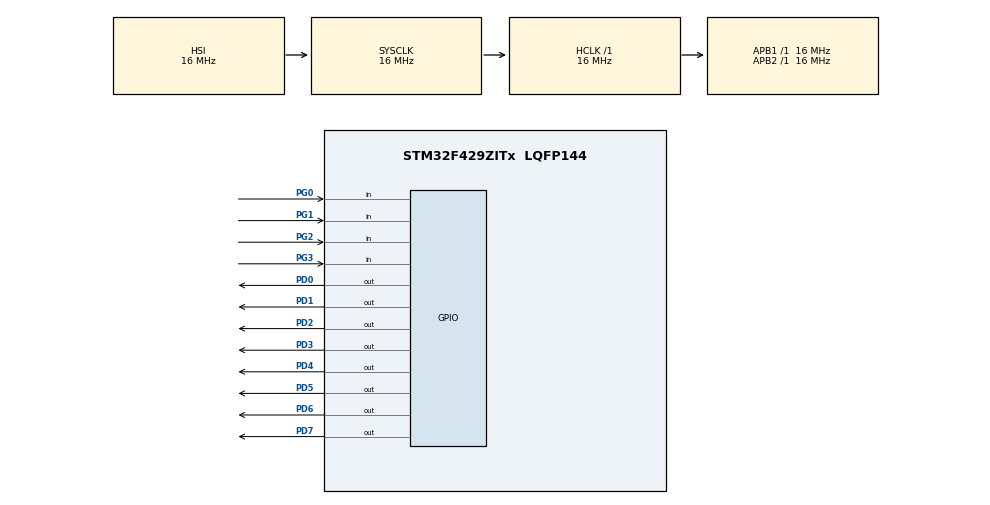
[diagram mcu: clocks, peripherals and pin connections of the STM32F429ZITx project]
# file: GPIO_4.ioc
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Mcu.Family=STM32F4
Mcu.Name=STM32F429ZITx
Mcu.Package=LQFP144
NVIC.PriorityGroup=NVIC_PRIORITYGROUP_4
PA13.Mode=Serial_Wire
PA13.Signal=SYS_JTMS-SWDIO
PA14.Mode=Serial_Wire
PA14.Signal=SYS_JTCK-SWCLK
PD0.GPIO_ModeDefaultOutputPP=GPIO_MODE_OUTPUT_PP
PD0.GPIO_PuPd=GPIO_PULLUP
PD0.GPIO_Speed=GPIO_SPEED_FREQ_HIGH
PD0.PinState=GPIO_PIN_RESET
PD0.Signal=GPIO_Output
PD1.GPIO_ModeDefaultOutputPP=GPIO_MODE_OUTPUT_PP
PD1.GPIO_PuPd=GPIO_PULLUP
PD1.GPIO_Speed=GPIO_SPEED_FREQ_HIGH
PD1.PinState=GPIO_PIN_RESET
PD1.Signal=GPIO_Output
PD2.GPIO_ModeDefaultOutputPP=GPIO_MODE_OUTPUT_PP
PD2.GPIO_PuPd=GPIO_PULLUP
PD2.GPIO_Speed=GPIO_SPEED_FREQ_HIGH
PD2.PinState=GPIO_PIN_RESET
PD2.Signal=GPIO_Output
PD3.GPIO_ModeDefaultOutputPP=GPIO_MODE_OUTPUT_PP
PD3.GPIO_PuPd=GPIO_PULLUP
PD3.GPIO_Speed=GPIO_SPEED_FREQ_HIGH
PD3.PinState=GPIO_PIN_RESET
PD3.Signal=GPIO_Output
PD4.GPIO_ModeDefaultOutputPP=GPIO_MODE_OUTPUT_PP
PD4.GPIO_PuPd=GPIO_PULLUP
PD4.GPIO_Speed=GPIO_SPEED_FREQ_HIGH
PD4.PinState=GPIO_PIN_RESET
PD4.Signal=GPIO_Output
PD5.GPIO_ModeDefaultOutputPP=GPIO_MODE_OUTPUT_PP
PD5.GPIO_PuPd=GPIO_PULLUP
PD5.GPIO_Speed=GPIO_SPEED_FREQ_HIGH
PD5.PinState=GPIO_PIN_RESET
PD5.Signal=GPIO_Output
PD6.GPIO_ModeDefaultOutputPP=GPIO_MODE_OUTPUT_PP
PD6.GPIO_PuPd=GPIO_PULLUP
PD6.GPIO_Speed=GPIO_SPEED_FREQ_HIGH
PD6.PinState=GPIO_PIN_RESET
PD6.Signal=GPIO_Output
PD7.GPIO_ModeDefaultOutputPP=GPIO_MODE_OUTPUT_PP
PD7.GPIO_PuPd=GPIO_PULLUP
PD7.GPIO_Speed=GPIO_SPEED_FREQ_HIGH
PD7.PinState=GPIO_PIN_RESET
PD7.Signal=GPIO_Output
PG0.GPIO_Mode=GPIO_MODE_INPUT
PG0.GPIO_PuPd=GPIO_PULLDOWN
PG0.Signal=GPIO_Input
PG1.GPIO_Mode=GPIO_MODE_INPUT
PG1.GPIO_PuPd=GPIO_PULLDOWN
PG1.Signal=GPIO_Input
PG2.GPIO_Mode=GPIO_MODE_INPUT
PG2.GPIO_PuPd=GPIO_PULLDOWN
PG2.Signal=GPIO_Input
PG3.GPIO_Mode=GPIO_MODE_INPUT
PG3.GPIO_PuPd=GPIO_PULLDOWN
PG3.Signal=GPIO_Input
ProjectManager.HeapSize=0x200
ProjectManager.StackSize=0x400
ProjectManager.TargetToolchain=STM32CubeIDE
RCC.AHBFreq_Value=16000000
RCC.APB1Freq_Value=16000000
RCC.APB2Freq_Value=16000000
RCC.CortexFreq_Value=16000000
RCC.HSE_VALUE=25000000
RCC.HSI_VALUE=16000000
RCC.LSE_VALUE=32768
RCC.SYSCLKFreq_VALUE=16000000
RCC.VCOOutputFreq_Value=192000000
board=custom

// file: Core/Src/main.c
/* USER CODE BEGIN Header */
/**
  ******************************************************************************
  * @file           : main.c
  * @brief          : Main program body
  ******************************************************************************
  * @attention
  *
  * Copyright (c) 2023 STMicroelectronics.
  * All rights reserved.
  *
  * This software is licensed under terms that can be found in the LICENSE file
  * in the root directory of this software component.
  * If no LICENSE file comes with this software, it is provided AS-IS.
  *
  ******************************************************************************
  */
/* USER CODE END Header */
#include "main.h"

void SystemClock_Config(void);
static void MX_GPIO_Init(void);
/* USER CODE BEGIN PFP */
void LED_OnOff(int, int);
/* USER CODE END PFP */

int main(void)
{
  /* USER CODE BEGIN 1 */

	unsigned char led = 0x01;

  /* USER CODE END 1 */

  /* MCU Configuration--------------------------------------------------------*/

  /* Reset of all peripherals, Initializes the Flash interface and the Systick. */
  HAL_Init();

  /* Configure the system clock */
  SystemClock_Config();

  /* Initialize all configured peripherals */
  MX_GPIO_Init();
  /* USER CODE BEGIN 2 */

  LED_OnOff(LED_ALL, 500);

  /* USER CODE END 2 */

  /* Infinite loop */
  /* USER CODE BEGIN WHILE */
  while (1)
  {
	  led = 0x00;

	  // -- SW1 이 눌러지면 -> led 의 1, 2번째 bit 을 1로 설정 (0x03 = 0000 0011)
	  if( HAL_GPIO_ReadPin(GPIO_SW, SW1 ) == RESET ) led = led | 0x03;
	  // -- SW2 이 눌러지면 -> led 의 3, 4번째 bit 을 1로 설정 (0x0c = 0000 1100)
	  if( HAL_GPIO_ReadPin(GPIO_SW, SW2 ) == RESET ) led = led | 0x0c;
	  // -- SW3 이 눌러지면 -> led 의 5, 6번째 bit 을 1로 설정 (0x30 = 0011 0000)
	  if( HAL_GPIO_ReadPin(GPIO_SW, SW3 ) == RESET ) led = led | 0x30;
	  // -- SW4 이 눌러지면 -> led 의 7, 8번째 bit 을 1로 설정 (0xc0 = 1100 0000)
	  if( HAL_GPIO_ReadPin(GPIO_SW, SW4 ) == RESET ) led = led | 0xc0;

	  LED_OnOff(led, 100);
    /* USER CODE END WHILE */

  }
}

void SystemClock_Config(void)
{
  RCC_OscInitTypeDef RCC_OscInitStruct = {0};
  RCC_ClkInitTypeDef RCC_ClkInitStruct = {0};

  /** Configure the main internal regulator output voltage
  */
  __HAL_RCC_PWR_CLK_ENABLE();
  __HAL_PWR_VOLTAGESCALING_CONFIG(PWR_REGULATOR_VOLTAGE_SCALE3);

  /** Initializes the RCC Oscillators according to the specified parameters
  * in the RCC_OscInitTypeDef structure.
  */
  RCC_OscInitStruct.OscillatorType = RCC_OSCILLATORTYPE_HSI;
  RCC_OscInitStruct.HSIState = RCC_HSI_ON;
  RCC_OscInitStruct.HSICalibrationValue = RCC_HSICALIBRATION_DEFAULT;
  RCC_OscInitStruct.PLL.PLLState = RCC_PLL_NONE;
  if (HAL_RCC_OscConfig(&RCC_OscInitStruct) != HAL_OK)
  {
    Error_Handler();
  }

  /** Initializes the CPU, AHB and APB buses clocks
  */
  RCC_ClkInitStruct.ClockType = RCC_CLOCKTYPE_HCLK|RCC_CLOCKTYPE_SYSCLK
                              |RCC_CLOCKTYPE_PCLK1|RCC_CLOCKTYPE_PCLK2;
  RCC_ClkInitStruct.SYSCLKSource = RCC_SYSCLKSOURCE_HSI;
  RCC_ClkInitStruct.AHBCLKDivider = RCC_SYSCLK_DIV1;
  RCC_ClkInitStruct.APB1CLKDivider = RCC_HCLK_DIV1;
  RCC_ClkInitStruct.APB2CLKDivider = RCC_HCLK_DIV1;

  if (HAL_RCC_ClockConfig(&RCC_ClkInitStruct, FLASH_LATENCY_0) != HAL_OK)
  {
    Error_Handler();
  }
}

static void MX_GPIO_Init(void)
{
  GPIO_InitTypeDef GPIO_InitStruct = {0};

  /* GPIO Ports Clock Enable */
  __HAL_RCC_GPIOG_CLK_ENABLE();
  __HAL_RCC_GPIOA_CLK_ENABLE();
  __HAL_RCC_GPIOD_CLK_ENABLE();

  /*Configure GPIO pin Output Level */
  HAL_GPIO_WritePin(GPIOD, GPIO_PIN_0|GPIO_PIN_1|GPIO_PIN_2|GPIO_PIN_3
                          |GPIO_PIN_4|GPIO_PIN_5|GPIO_PIN_6|GPIO_PIN_7, GPIO_PIN_RESET);

  /*Configure GPIO pins : PG0 PG1 PG2 PG3 */
  GPIO_InitStruct.Pin = GPIO_PIN_0|GPIO_PIN_1|GPIO_PIN_2|GPIO_PIN_3;
  GPIO_InitStruct.Mode = GPIO_MODE_INPUT;
  GPIO_InitStruct.Pull = GPIO_PULLDOWN;
  HAL_GPIO_Init(GPIOG, &GPIO_InitStruct);

  /*Configure GPIO pins : PD0 PD1 PD2 PD3
                           PD4 PD5 PD6 PD7 */
  GPIO_InitStruct.Pin = GPIO_PIN_0|GPIO_PIN_1|GPIO_PIN_2|GPIO_PIN_3
                          |GPIO_PIN_4|GPIO_PIN_5|GPIO_PIN_6|GPIO_PIN_7;
  GPIO_InitStruct.Mode = GPIO_MODE_OUTPUT_PP;
  GPIO_InitStruct.Pull = GPIO_PULLUP;
  GPIO_InitStruct.Speed = GPIO_SPEED_FREQ_HIGH;
  HAL_GPIO_Init(GPIOD, &GPIO_InitStruct);

}

/* USER CODE BEGIN 4 */

void LED_OnOff(int led, int interval)
{
	HAL_GPIO_WritePin(GPIO_LED, led, GPIO_PIN_SET );
	HAL_Delay(interval);
	HAL_GPIO_WritePin(GPIO_LED, led, GPIO_PIN_RESET );
}

/* USER CODE END 4 */

void Error_Handler(void)
{
  __disable_irq();
  while (1)
  {
  }
}
